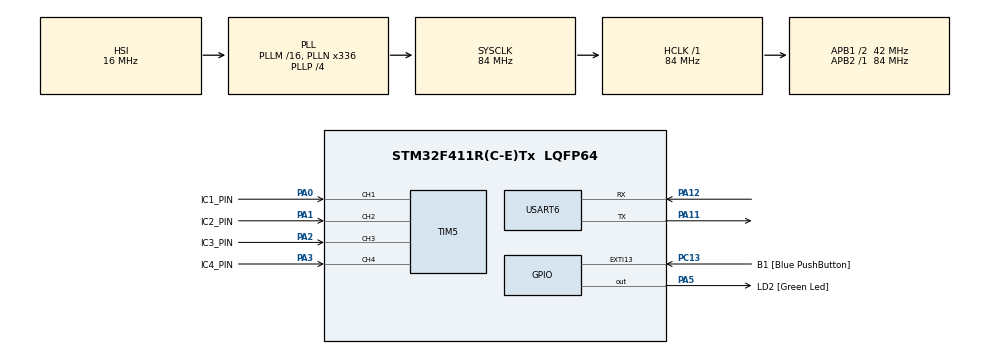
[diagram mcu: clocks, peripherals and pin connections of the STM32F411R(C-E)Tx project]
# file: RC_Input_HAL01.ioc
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Mcu.Family=STM32F4
Mcu.Name=STM32F411R(C-E)Tx
Mcu.Package=LQFP64
NVIC.PriorityGroup=NVIC_PRIORITYGROUP_0
NVIC.TIM5_IRQn=true\:0\:0\:false
PA0-WKUP.GPIO_Label=IC1_PIN
PA0-WKUP.GPIO_ModeDefaultPP=GPIO_MODE_AF_PP
PA0-WKUP.GPIO_PuPd=GPIO_NOPULL
PA0-WKUP.GPIO_Speed=GPIO_SPEED_LOW
PA0-WKUP.Signal=S_TIM5_CH1
PA1.GPIO_Label=IC2_PIN
PA1.GPIO_ModeDefaultPP=GPIO_MODE_AF_PP
PA1.GPIO_PuPd=GPIO_NOPULL
PA1.GPIO_Speed=GPIO_SPEED_LOW
PA1.Signal=S_TIM5_CH2
PA11.Mode=Asynchronous
PA11.Signal=USART6_TX
PA12.Mode=Asynchronous
PA12.Signal=USART6_RX
PA13.GPIO_Label=TMS
PA13.Mode=Serial-Wire
PA13.Signal=SYS_JTMS-SWDIO
PA14.GPIO_Label=TCK
PA14.Mode=Serial-Wire
PA14.Signal=SYS_JTCK-SWCLK
PA2.GPIO_Label=IC3_PIN
PA2.GPIO_ModeDefaultPP=GPIO_MODE_AF_PP
PA2.GPIO_PuPd=GPIO_NOPULL
PA2.GPIO_Speed=GPIO_SPEED_LOW
PA2.Signal=S_TIM5_CH3
PA3.GPIO_Label=IC4_PIN
PA3.GPIO_ModeDefaultPP=GPIO_MODE_AF_PP
PA3.GPIO_PuPd=GPIO_NOPULL
PA3.GPIO_Speed=GPIO_SPEED_LOW
PA3.Signal=S_TIM5_CH4
PA5.GPIO_Label=LD2 [Green Led]
PA5.GPIO_ModeDefaultOutputPP=GPIO_MODE_OUTPUT_PP
PA5.GPIO_PuPd=GPIO_NOPULL
PA5.GPIO_Speed=GPIO_SPEED_LOW
PA5.Signal=GPIO_Output
PB3.GPIO_Label=SWO
PB3.Signal=SYS_JTDO-SWO
PC13-ANTI_TAMP.GPIO_Label=B1 [Blue PushButton]
PC13-ANTI_TAMP.GPIO_ModeDefaultEXTI=GPIO_MODE_EVT_RISING
PC13-ANTI_TAMP.GPIO_PuPd=GPIO_NOPULL
PC13-ANTI_TAMP.Signal=GPXTI13
PC14-OSC32_IN.Signal=RCC_OSC32_IN
PC15-OSC32_OUT.Signal=RCC_OSC32_OUT
PH0\ -\ OSC_IN.Signal=RCC_OSC_IN
PH1\ -\ OSC_OUT.Signal=RCC_OSC_OUT
ProjectManager.TargetToolchain=SW4STM32
RCC.48MHZClocksFreq_Value=84000000
RCC.AHBFreq_Value=84000000
RCC.APB1CLKDivider=RCC_HCLK_DIV2
RCC.APB1Freq_Value=42000000
RCC.APB1TimFreq_Value=84000000
RCC.APB2Freq_Value=84000000
RCC.APB2TimFreq_Value=84000000
RCC.CortexFreq_Value=10500000
RCC.HCLKFreq_Value=84000000
RCC.HSE_VALUE=8000000
RCC.HSI_VALUE=16000000
RCC.LSE_VALUE=32768
RCC.PLLN=336
RCC.PLLP=RCC_PLLP_DIV4
RCC.SYSCLKFreq_VALUE=84000000
RCC.SYSCLKSource=RCC_SYSCLKSOURCE_PLLCLK
RCC.VCOOutputFreq_Value=336000000
SH.S_TIM5_CH1.0=TIM5_CH1,Input_Capture1_from_TI1
SH.S_TIM5_CH2.0=TIM5_CH2,Input_Capture2_from_TI2
SH.S_TIM5_CH3.0=TIM5_CH3,Input_Capture3_from_TI3
SH.S_TIM5_CH4.0=TIM5_CH4,Input_Capture4_from_TI4
TIM5.Channel-Input_Capture2_from_TI2=TIM_CHANNEL_2
TIM5.Channel-Input_Capture3_from_TI3=TIM_CHANNEL_3
TIM5.Channel-Input_Capture4_from_TI4=TIM_CHANNEL_4
TIM5.ICPolarity_CH1=TIM_INPUTCHANNELPOLARITY_BOTHEDGE
TIM5.ICPolarity_CH2=TIM_INPUTCHANNELPOLARITY_BOTHEDGE
TIM5.ICPolarity_CH3=TIM_INPUTCHANNELPOLARITY_BOTHEDGE
TIM5.ICPolarity_CH4=TIM_INPUTCHANNELPOLARITY_BOTHEDGE
VP_TIM5_VS_ClockSourceINT.Mode=Internal

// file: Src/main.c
/**
  ******************************************************************************
  * File Name          : main.c
  * Date               : 04/04/2015 18:38:14
  * Description        : Main program body
  ******************************************************************************
  *
  * COPYRIGHT(c) 2015 STMicroelectronics
  *
  * Redistribution and use in source and binary forms, with or without modification,
  * are permitted provided that the following conditions are met:
  *   1. Redistributions of source code must retain the above copyright notice,
  *      this list of conditions and the following disclaimer.
  *   2. Redistributions in binary form must reproduce the above copyright notice,
  *      this list of conditions and the following disclaimer in the documentation
  *      and/or other materials provided with the distribution.
  *   3. Neither the name of STMicroelectronics nor the names of its contributors
  *      may be used to endorse or promote products derived from this software
  *      without specific prior written permission.
  *
  * THIS SOFTWARE IS PROVIDED BY THE COPYRIGHT HOLDERS AND CONTRIBUTORS "AS IS"
  * AND ANY EXPRESS OR IMPLIED WARRANTIES, INCLUDING, BUT NOT LIMITED TO, THE
  * IMPLIED WARRANTIES OF MERCHANTABILITY AND FITNESS FOR A PARTICULAR PURPOSE ARE
  * DISCLAIMED. IN NO EVENT SHALL THE COPYRIGHT HOLDER OR CONTRIBUTORS BE LIABLE
  * FOR ANY DIRECT, INDIRECT, INCIDENTAL, SPECIAL, EXEMPLARY, OR CONSEQUENTIAL
  * DAMAGES (INCLUDING, BUT NOT LIMITED TO, PROCUREMENT OF SUBSTITUTE GOODS OR
  * SERVICES; LOSS OF USE, DATA, OR PROFITS; OR BUSINESS INTERRUPTION) HOWEVER
  * CAUSED AND ON ANY THEORY OF LIABILITY, WHETHER IN CONTRACT, STRICT LIABILITY,
  * OR TORT (INCLUDING NEGLIGENCE OR OTHERWISE) ARISING IN ANY WAY OUT OF THE USE
  * OF THIS SOFTWARE, EVEN IF ADVISED OF THE POSSIBILITY OF SUCH DAMAGE.
  *
  ******************************************************************************
  */

#include "stm32f4xx_hal.h"
#include "tim.h"
#include "usart.h"
#include "gpio.h"

/* USER CODE BEGIN Includes */
//Global variable to store Captured Timer for CC1
uint16_t IC1Capture = 0;
/* USER CODE END Includes */

void SystemClock_Config(void);

int main(void){
	int i=0;

	/* MCU Configuration----------------------------------------------------------*/

	/* Reset of all peripherals, Initializes the Flash interface and the Systick. */
	HAL_Init();

	/* Configure the system clock */
	SystemClock_Config();

	/* Initialize all configured peripherals */
	MX_GPIO_Init();
	MX_TIM5_Init();
	MX_USART6_UART_Init();

	/* USER CODE BEGIN 2 */
	/* Output a message on Hyperterminal using printf function */
	printf("\n\r UART Printf Example: retarget the C library printf function to the UART\n\r");

	/* USER CODE END 2 */

	/* Infinite loop */
	/* USER CODE BEGIN WHILE */
	while (1){
		// put message on UART6
		printf("%d\r\n", IC1Capture);
		for(i=0;i<5000000;i++);
	}
	/* USER CODE END 3 */

}

/** System Clock Configuration
*/
void SystemClock_Config(void)
{

  RCC_OscInitTypeDef RCC_OscInitStruct;
  RCC_ClkInitTypeDef RCC_ClkInitStruct;

  __PWR_CLK_ENABLE();

  __HAL_PWR_VOLTAGESCALING_CONFIG(PWR_REGULATOR_VOLTAGE_SCALE2);

  RCC_OscInitStruct.OscillatorType = RCC_OSCILLATORTYPE_HSI|RCC_OSCILLATORTYPE_LSI;
  RCC_OscInitStruct.HSIState = RCC_HSI_ON;
  RCC_OscInitStruct.HSICalibrationValue = 16;
  RCC_OscInitStruct.LSIState = RCC_LSI_ON;
  RCC_OscInitStruct.PLL.PLLState = RCC_PLL_ON;
  RCC_OscInitStruct.PLL.PLLSource = RCC_PLLSOURCE_HSI;
  RCC_OscInitStruct.PLL.PLLM = 16;
  RCC_OscInitStruct.PLL.PLLN = 336;
  RCC_OscInitStruct.PLL.PLLP = RCC_PLLP_DIV4;
  RCC_OscInitStruct.PLL.PLLQ = 4;
  HAL_RCC_OscConfig(&RCC_OscInitStruct);

  RCC_ClkInitStruct.ClockType = RCC_CLOCKTYPE_SYSCLK|RCC_CLOCKTYPE_PCLK1;
  RCC_ClkInitStruct.SYSCLKSource = RCC_SYSCLKSOURCE_PLLCLK;
  RCC_ClkInitStruct.AHBCLKDivider = RCC_SYSCLK_DIV1;
  RCC_ClkInitStruct.APB1CLKDivider = RCC_HCLK_DIV2;
  RCC_ClkInitStruct.APB2CLKDivider = RCC_HCLK_DIV1;
  HAL_RCC_ClockConfig(&RCC_ClkInitStruct, FLASH_LATENCY_2);

}

/************************ (C) COPYRIGHT STMicroelectronics *****END OF FILE****/
